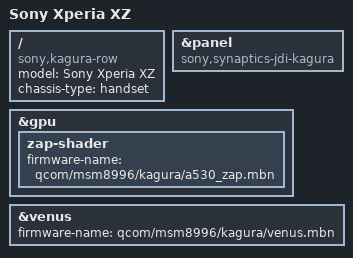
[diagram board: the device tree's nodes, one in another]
// SPDX-License-Identifier: BSD-3-Clause
/*
 * Copyright (c) 2021, AngeloGioacchino Del Regno
 *                     <angelogioacchino.delregno@somainline.org>
 * Copyright (c) 2021, Konrad Dybcio <konrad.dybcio@somainline.org>
 */

/dts-v1/;

#include "msm8996-sony-xperia-tone.dtsi"

/ {
	model = "Sony Xperia XZ";
	compatible = "sony,kagura-row", "qcom,msm8996";
	chassis-type = "handset";
};

&panel {
	compatible = "sony,synaptics-jdi-kagura";
};

&gpu {
	zap-shader {
		firmware-name = "qcom/msm8996/kagura/a530_zap.mbn";
	};
};

&venus {
	firmware-name = "qcom/msm8996/kagura/venus.mbn";
};
